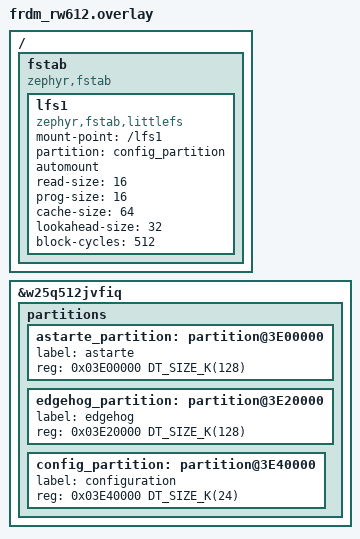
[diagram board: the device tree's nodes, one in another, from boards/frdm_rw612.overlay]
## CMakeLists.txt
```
# (C) Copyright 2025, SECO Mind Srl
#
# SPDX-License-Identifier: Apache-2.0

function(concat_if_exists FILE_PATH STRING_NAME)
    # Check if the file exists
    file(GLOB FILE_TO_ADD ${FILE_PATH})

    # If the file exists, add it to the list
    if(EXISTS ${FILE_TO_ADD})
        set(${STRING_NAME} "${${STRING_NAME}};${FILE_PATH}" PARENT_SCOPE)
    endif()
endfunction()

cmake_minimum_required(VERSION 3.20.0)

# add the sample specific private configuration
concat_if_exists(${CMAKE_SOURCE_DIR}/private.conf EXTRA_CONF_FILE)

find_package(Zephyr REQUIRED HINTS $ENV{ZEPHYR_BASE})
project(cpu_metrics_app)

test_sysbuild()

# create source files list
FILE(GLOB app_common_sources ${CMAKE_CURRENT_LIST_DIR}/src/*.c)
if(NOT CONFIG_WIFI)
    LIST(REMOVE_ITEM app_common_sources ${CMAKE_CURRENT_LIST_DIR}/src/wifi.c)
endif()
target_sources(app PRIVATE ${app_common_sources})
target_include_directories(app PRIVATE ${CMAKE_CURRENT_LIST_DIR}/include)

# add generated sources and includes for the interfaces
FILE(GLOB app_interfaces_sources ${CMAKE_CURRENT_LIST_DIR}/interfaces/*.c)
target_sources(app PRIVATE ${app_interfaces_sources})
target_include_directories(app PRIVATE ${CMAKE_CURRENT_LIST_DIR}/interfaces)
```

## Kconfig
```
menu "Zephyr"
source "Kconfig.zephyr"
endmenu

menu "CPU metrics sample application"

config GET_CONFIG_FROM_FLASH
    bool "Collect the configuration from flash"
    help
        Collect the configuration from a file in the dedicated flash partition.

config WIFI_SSID
    string "WiFi SSID"
	depends on WIFI
    depends on !GET_CONFIG_FROM_FLASH
    default ""
	help
	  WiFi access point SSID.

config WIFI_PASSWORD
    string "WiFi password"
	depends on WIFI
    depends on !GET_CONFIG_FROM_FLASH
    default ""
    help
        WiFi access point password.

config ENABLE_TRANSMISSION
    bool "Enable sensor readings transmission"
    default n
    help
        Enable transmission of sensor readings to Astarte.

config CPU_TEMP_SENSOR
    bool "CPU temperature sensor"
    default n
    help
        Temperature sensor embedded within the CPU die.

config AMBIENT_TEMP_SENSOR
    bool "Ambient temperature sensor"
    default n
    help
        Temperature sensor embedded within the ambient.

config ASTARTE_DEVICE_ID
	string "Astarte device ID"
    depends on !GET_CONFIG_FROM_FLASH
    default ""
	help
	  Device ID to be used to connect to Astarte.

config ASTARTE_CREDENTIAL_SECRET
    string "Astarte credential secret"
    depends on !GET_CONFIG_FROM_FLASH
    default ""
    help
        The credential secret to be used to connect to Astarte.

config SAMPLE_DURATION_SECONDS
    int "Sample maximum duration (s)"
    default 0
    help
        Use this setting to change for how long the sample will run.
        When set to 0 the sample will run indefinitely.

endmenu

module = APP
module-str = APP
source "subsys/logging/Kconfig.template.log_config"
```

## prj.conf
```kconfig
# (C) Copyright 2025, SECO Mind Srl
#
# SPDX-License-Identifier: Apache-2.0
#
# This is a Kconfig fragment which can be used to enable debug-related options
# in the application. See the README for more details.

# Enable logging with floating point support
CONFIG_LOG=y
CONFIG_CBPRINTF_FP_SUPPORT=y

# Increased stack size
CONFIG_MAIN_STACK_SIZE=8192

# Enable base64 encoding and decoding
CONFIG_BASE64=y

# Enable system hashmaps
CONFIG_SYS_HASH_MAP=y
CONFIG_SYS_HASH_FUNC32=y

# Enable JSON library
CONFIG_JSON_LIBRARY=y

# Enable entropy generator
CONFIG_ENTROPY_GENERATOR=y

# DNS resolver
CONFIG_DNS_RESOLVER=y
CONFIG_DNS_SERVER_IP_ADDRESSES=y
CONFIG_DNS_SERVER1="8.8.8.8" # Google DNS

# MbedTLS
CONFIG_MBEDTLS=y
CONFIG_MBEDTLS_BUILTIN=y
CONFIG_MBEDTLS_ENABLE_HEAP=y
# 55kB is the max absolute value, could be set much lower
CONFIG_MBEDTLS_HEAP_SIZE=95000
# 16384 is the max absolute value, could be set much lower
CONFIG_MBEDTLS_SSL_MAX_CONTENT_LEN=16384
CONFIG_MBEDTLS_PEM_CERTIFICATE_FORMAT=y
CONFIG_MBEDTLS_PK_WRITE_C=y # Required for PEM writing
CONFIG_MBEDTLS_ENTROPY_C=y
CONFIG_MBEDTLS_ENTROPY_POLL_ZEPHYR=y
CONFIG_MBEDTLS_TLS_VERSION_1_2=y
CONFIG_MBEDTLS_CIPHER=y
CONFIG_MBEDTLS_CIPHER_ALL_ENABLED=y
CONFIG_MBEDTLS_SERVER_NAME_INDICATION=y
CONFIG_MBEDTLS_KEY_EXCHANGE_ALL_ENABLED=y
CONFIG_MBEDTLS_HASH_ALL_ENABLED=y
CONFIG_MBEDTLS_CTR_DRBG_ENABLED=y
CONFIG_MBEDTLS_HMAC_DRBG_ENABLED=y
CONFIG_MBEDTLS_CHACHAPOLY_AEAD_ENABLED=y
CONFIG_MBEDTLS_ECDH_C=y
CONFIG_MBEDTLS_ECDSA_C=y
CONFIG_MBEDTLS_ECJPAKE_C=y
CONFIG_MBEDTLS_ECP_C=y
CONFIG_MBEDTLS_ECP_ALL_ENABLED=y
CONFIG_MBEDTLS_GENPRIME_ENABLED=y
CONFIG_MBEDTLS_PKCS5_C=y
CONFIG_MBEDTLS_X509_CRL_PARSE_C=y
CONFIG_MBEDTLS_X509_CSR_PARSE_C=y
CONFIG_MBEDTLS_X509_CSR_WRITE_C=y

# Enable networking
CONFIG_NETWORKING=y

# Sockets
CONFIG_NET_SOCKETS=y
CONFIG_NET_SOCKETS_POLL_MAX=4
CONFIG_NET_SOCKETS_SOCKOPT_TLS=y

# Use DHCP for IPv4 and IPv6
CONFIG_NET_DHCPV4=y
CONFIG_NET_DHCPV6=y

# Generic networking options
CONFIG_NET_TX_STACK_SIZE=4096
CONFIG_NET_RX_STACK_SIZE=4096
CONFIG_NET_PKT_RX_COUNT=20
CONFIG_NET_PKT_TX_COUNT=20
CONFIG_NET_BUF_RX_COUNT=40
CONFIG_NET_BUF_TX_COUNT=40
CONFIG_NET_MAX_CONTEXTS=20
CONFIG_NET_MGMT=y
CONFIG_NET_MGMT_EVENT=y
CONFIG_NET_IPV4=y
CONFIG_NET_IPV6=y
CONFIG_NET_TCP=y

# Enable HTTP client
CONFIG_HTTP_CLIENT=y

# MQTT options
CONFIG_MQTT_LIB=y
CONFIG_MQTT_LIB_TLS=y
CONFIG_MQTT_KEEPALIVE=60

# Enable flash
CONFIG_FLASH=y
CONFIG_FLASH_MAP=y
CONFIG_FLASH_PAGE_LAYOUT=y

# Enable NVS
CONFIG_NVS=y
CONFIG_NVS_LOG_LEVEL_WRN=y

# Astarte device SDK
CONFIG_ASTARTE_DEVICE_SDK=y
CONFIG_ASTARTE_DEVICE_SDK_HOSTNAME="."
CONFIG_ASTARTE_DEVICE_SDK_REALM_NAME="."
# The two certificate tags are the same as the root CA is the same for Astarte API and MQTT broker.
CONFIG_ASTARTE_DEVICE_SDK_HTTPS_CA_CERT_TAG=1
CONFIG_ASTARTE_DEVICE_SDK_MQTTS_CA_CERT_TAG=1
CONFIG_ASTARTE_DEVICE_SDK_CLIENT_CERT_TAG=2
CONFIG_ASTARTE_DEVICE_SDK_PAIRING_JWT=""
CONFIG_ASTARTE_DEVICE_SDK_PERMANENT_STORAGE=y

# Configure the name of the binary
# This will also be used to identify the edgehog image
CONFIG_KERNEL_BIN_NAME="frdm-rw612"

# Edgehog depends on
CONFIG_IMG_MANAGER=y
CONFIG_STREAM_FLASH=y
CONFIG_REBOOT=y

# Edgehog device
CONFIG_EDGEHOG_DEVICE=y
CONFIG_EDGEHOG_DEVICE_CA_CERT_OTA_TAG=3
CONFIG_EDGEHOG_DEVICE_ZBUS_OTA_EVENT=y

# System info interface data
CONFIG_EDGEHOG_DEVICE_PART_NUMBER="FRDM-RW612-X"
CONFIG_EDGEHOG_DEVICE_SERIAL_NUMBER=""

# Sample configuration
CONFIG_ASTARTE_DEVICE_ID="......................"
CONFIG_ASTARTE_CREDENTIAL_SECRET="."

CONFIG_DNS_RESOLVER_AI_MAX_ENTRIES=4
CONFIG_NET_SOCKETS_TLS_MAX_CONTEXTS=4

CONFIG_THREAD_MONITOR=y
CONFIG_INIT_STACKS=y
CONFIG_THREAD_STACK_INFO=y

CONFIG_ZVFS_OPEN_MAX=16

CONFIG_POSIX_TIMERS=y
CONFIG_SNTP=y
CONFIG_NET_CONFIG_CLOCK_SNTP_INIT=y
CONFIG_NET_CONFIG_SNTP_INIT_SERVER="0.pool.ntp.org"
CONFIG_NET_CONFIG_SNTP_INIT_TIMEOUT=3000

# Enable the settings
CONFIG_SETTINGS=y

# Activate Zbus
CONFIG_ZBUS=y

# Configuration for the CPU temperature sensor
CONFIG_SENSOR=y

# Configuration for the collection of CPU statistics
CONFIG_THREAD_RUNTIME_STATS=y
CONFIG_SCHED_THREAD_USAGE=y
CONFIG_SCHED_THREAD_USAGE_ALL=y
CONFIG_SCHED_THREAD_USAGE_ANALYSIS=y
CONFIG_SCHED_THREAD_USAGE_AUTO_ENABLE=y

# Enable littlefs
CONFIG_FILE_SYSTEM=y
CONFIG_FILE_SYSTEM_LITTLEFS=y

# Enabling shell
CONFIG_SHELL=y
CONFIG_SHELL_AUTOSTART=y
```

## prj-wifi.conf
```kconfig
# (C) Copyright 2025, SECO Mind Srl
#
# SPDX-License-Identifier: Apache-2.0
#
# This is a Kconfig fragment which can be used to enable debug-related options
# in the application. See the README for more details.

CONFIG_WIFI=y
CONFIG_ETH_DRIVER=n

CONFIG_NET_IPV6=n
CONFIG_NET_DHCPV6=n

# Increased stack size for network management
CONFIG_NET_MGMT_EVENT_STACK_SIZE=2048

# Large shell stack size used when configuring WiFi through shell
CONFIG_SHELL_STACK_SIZE=16384
CONFIG_SHELL_GETOPT=y
CONFIG_GETOPT_LONG=y
```

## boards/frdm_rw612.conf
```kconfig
# (C) Copyright 2025, SECO Mind Srl
#
# SPDX-License-Identifier: Apache-2.0

# Enable the WiFi
CONFIG_WIFI_NXP=y

# Use a large log buffer size
CONFIG_LOG_BUFFER_SIZE=32768

# Set the ambient temperature sensor in the demo
CONFIG_AMBIENT_TEMP_SENSOR=y

# This board by default will expect the configuration to be present in flash
CONFIG_GET_CONFIG_FROM_FLASH=y
```

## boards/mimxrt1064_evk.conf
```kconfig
# (C) Copyright 2025, SECO Mind Srl
#
# SPDX-License-Identifier: Apache-2.0

# Ethernet settings
CONFIG_NET_L2_ETHERNET=y
CONFIG_NET_L2_ETHERNET_MGMT=y

CONFIG_EDGEHOG_DEVICE_USE_EDGEHOG_PARTITION=y

CONFIG_LOG_MODE_DEFERRED=y
CONFIG_LOG_BUFFER_SIZE=32768

CONFIG_CPU_TEMP_SENSOR=y
```

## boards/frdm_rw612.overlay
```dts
/*
 * (C) Copyright 2025, SECO Mind Srl
 *
 * SPDX-License-Identifier: Apache-2.0
 */

/ {
    fstab {
        compatible = "zephyr,fstab";
        lfs1: lfs1 {
            compatible = "zephyr,fstab,littlefs";
            mount-point = "/lfs1";
            partition = <&config_partition>;
            automount;
            read-size = <16>;
            prog-size = <16>;
            cache-size = <64>;
            lookahead-size = <32>;
            block-cycles = <512>;
        };
    };
};

&w25q512jvfiq {
	partitions {
		astarte_partition: partition@3E00000 {
			label = "astarte";
			reg = <0x03E00000 DT_SIZE_K(128)>;
		};
		edgehog_partition: partition@3E20000 {
			label = "edgehog";
			reg = <0x03E20000 DT_SIZE_K(128)>;
		};
		config_partition: partition@3E40000 {
			label = "configuration";
			reg = <0x03E40000 DT_SIZE_K(24)>;
		};
	};
};
```

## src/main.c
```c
/*
 * (C) Copyright 2025, SECO Mind Srl
 *
 * SPDX-License-Identifier: Apache-2.0
 */

#include <zephyr/device.h>
#include <zephyr/drivers/sensor.h>
#include <zephyr/kernel.h>
#include <zephyr/logging/log.h>
#include <zephyr/net/net_mgmt.h>
#include <zephyr/net/sntp.h>
#include <zephyr/posix/time.h>
LOG_MODULE_REGISTER(cpu_metrics_app, CONFIG_APP_LOG_LEVEL);

#if (!defined(CONFIG_ASTARTE_DEVICE_SDK_DEVELOP_USE_NON_TLS_HTTP)                                  \
    || !defined(CONFIG_ASTARTE_DEVICE_SDK_DEVELOP_USE_NON_TLS_MQTT))
#include <zephyr/net/tls_credentials.h>

#include "ca_certificates.h"
#endif

#include <astarte_device_sdk/device.h>

#ifdef CONFIG_EDGEHOG_DEVICE_ZBUS_OTA_EVENT
#include <edgehog_device/ota_event.h>
#endif
#include <edgehog_device/device.h>
#include <edgehog_device/telemetry.h>

#if defined(CONFIG_WIFI)
#include "wifi.h"
#else
#include "eth.h"
#endif
#include "generated_interfaces.h"

#include "sample_config.h"

/************************************************
 * Constants and defines
 ***********************************************/

#define MAIN_THREAD_PERIOD_MS 500
#define EDGEHOG_DEVICE_PERIOD_MS 100
#ifdef CONFIG_EDGEHOG_DEVICE_ZBUS_OTA_EVENT
#define ZBUS_PERIOD_MS 500
#endif

#define HTTP_TIMEOUT_MS (3 * MSEC_PER_SEC)
#define MQTT_FIRST_POLL_TIMEOUT_MS (3 * MSEC_PER_SEC)
#define MQTT_POLL_TIMEOUT_MS 200

#define TELEMETRY_PERIOD_S 5

#define EDGEHOG_DEVICE_THREAD_STACK_SIZE 16384
#define EDGEHOG_DEVICE_THREAD_PRIORITY 0
K_THREAD_STACK_DEFINE(edgehog_device_thread_stack_area, EDGEHOG_DEVICE_THREAD_STACK_SIZE);
static struct k_thread edgehog_device_thread_data;

#ifdef CONFIG_EDGEHOG_DEVICE_ZBUS_OTA_EVENT
#define ZBUS_THREAD_STACK_SIZE 16384
#define ZBUS_THREAD_PRIORITY 0
K_THREAD_STACK_DEFINE(zbus_thread_stack_area, ZBUS_THREAD_STACK_SIZE);
static struct k_thread zbus_thread_data;
#define EDGEHOG_OTA_SUBSCRIBER_NOTIFICATION_QUEUE_SIZE 5
#define EDGEHOG_OTA_OBSERVER_NOTIFY_PRIORITY 5
ZBUS_SUBSCRIBER_DEFINE(edgehog_ota_subscriber, EDGEHOG_OTA_SUBSCRIBER_NOTIFICATION_QUEUE_SIZE);
ZBUS_CHAN_ADD_OBS(edgehog_ota_chan, edgehog_ota_subscriber, EDGEHOG_OTA_OBSERVER_NOTIFY_PRIORITY);
#endif

#define STATS_THREAD_STACK_SIZE 16384
#define STATS_THREAD_PRIORITY 0
K_THREAD_STACK_DEFINE(stats_thread_stack_area, STATS_THREAD_STACK_SIZE);
static struct k_thread stats_thread_data;

#ifdef CONFIG_CPU_TEMP_SENSOR
static const struct device *const die_temp_sensor = DEVICE_DT_GET(DT_ALIAS(die_temp0));
#endif
#ifdef CONFIG_AMBIENT_TEMP_SENSOR
static const struct device *const ambient_temp_sensor = DEVICE_DT_GET(DT_ALIAS(ambient_temp0));
#endif

enum device_tread_flags
{
    DEVICE_THREADS_FLAGS_TERMINATION = 1U,
    DEVICE_THREADS_FLAGS_ASTARTE_CONNECTED,
};
static atomic_t device_threads_flags;

static edgehog_device_handle_t edgehog_device;

/************************************************
 * Static functions declaration
 ***********************************************/

/**
 * @brief Initialize System Time
 */
static void system_time_init(void);
/**
 * @brief Entry point for the Astarte device thread.
 *
 * @param arg1 Unused argument.
 * @param arg2 Unused argument.
 * @param arg3 Unused argument.
 */
static void edgehog_device_thread_entry_point(void *device_id, void *cred_secr, void *arg3);
#ifdef CONFIG_EDGEHOG_DEVICE_ZBUS_OTA_EVENT
/**
 * @brief Entry point for the Zbus reception thread.
 *
 * @param arg1 Unused argument.
 * @param arg2 Unused argument.
 * @param arg3 Unused argument.
 */
static void zbus_thread_entry_point(void *arg1, void *arg2, void *arg3);
#endif
#ifdef CONFIG_EDGEHOG_DEVICE_ZBUS_OTA_EVENT
/**
 * @brief Listen on the Edgehog zbus channel for events.
 *
 * @param timeout The timeout used for listening. In case of a received notification this timeout
 * is also used for reading the message.
 */
static void edgehog_listen_zbus_channel(k_timeout_t timeout);
#endif
/**
 * @brief Callback handler for Astarte connection events.
 *
 * @param event Astarte device connection event.
 */
static void astarte_connection_callback(astarte_device_connection_event_t event);
/**
 * @brief Callback handler for Astarte disconnection events.
 *
 * @param event Astarte device disconnection event.
 */
static void astarte_disconnection_callback(astarte_device_disconnection_event_t event);
/**
 * @brief Entry point for the stats thread.
 *
 * @param arg1 Unused argument.
 * @param arg2 Unused argument.
 * @param arg3 Unused argument.
 */
static void stats_thread_entry_point(void *arg1, void *arg2, void *arg3);

/************************************************
 * Global functions definition
 ***********************************************/

// NOLINTNEXTLINE(hicpp-function-size)
int main(void)
{
    LOG_INF("Edgehog device sample");
    LOG_INF("Board: %s", CONFIG_BOARD);

    struct sample_config cfg_from_file = { 0 };
    sample_config_get(&cfg_from_file);
    LOG_INF("Configured device ID: %s", cfg_from_file.device_id);
    LOG_INF("Configured credential secret: %s", cfg_from_file.credential_secret);
#if defined(CONFIG_WIFI)
    LOG_INF("Configured WiFi SSID: %s", cfg_from_file.wifi_ssid);
    LOG_INF("Configured WiFi password: %s", cfg_from_file.wifi_pwd);
#endif

#ifdef CONFIG_CPU_TEMP_SENSOR
    if (!device_is_ready(die_temp_sensor)) {
        LOG_ERR("sensor: device %s not ready.", die_temp_sensor->name);
        return -ENODEV;
    }
#endif
#ifdef CONFIG_AMBIENT_TEMP_SENSOR
    if (!device_is_ready(ambient_temp_sensor)) {
        LOG_ERR("sensor: device %s not ready.", ambient_temp_sensor->name);
        return -ENODEV;
    }
#endif

#if defined(CONFIG_WIFI)
    LOG_INF("Initializing WiFi driver."); // NOLINT
    app_wifi_init();
    k_sleep(K_SECONDS(5));
    enum wifi_security_type sec = WIFI_SECURITY_TYPE_PSK;
    if (app_wifi_connect(cfg_from_file.wifi_ssid, sec, cfg_from_file.wifi_pwd) != 0) {
        LOG_ERR("Connectivity intialization failed!"); // NOLINT
        return -1;
    }
#else
    LOG_INF("Initializing Ethernet driver."); // NOLINT
    if (eth_connect() != 0) {
        LOG_ERR("Connectivity intialization failed!"); // NOLINT
        return -1;
    }
#endif

    // Add TLS certificate for Astarte if required
#if (!defined(CONFIG_ASTARTE_DEVICE_SDK_DEVELOP_USE_NON_TLS_HTTP)                                  \
    || !defined(CONFIG_ASTARTE_DEVICE_SDK_DEVELOP_USE_NON_TLS_MQTT))
    tls_credential_add(CONFIG_ASTARTE_DEVICE_SDK_HTTPS_CA_CERT_TAG, TLS_CREDENTIAL_CA_CERTIFICATE,
        ca_certificate_root, sizeof(ca_certificate_root));
#endif
    // Add TLS certificate for Edgehog if required
#if !defined(CONFIG_EDGEHOG_DEVICE_DEVELOP_DISABLE_OR_IGNORE_TLS)
    tls_credential_add(CONFIG_EDGEHOG_DEVICE_CA_CERT_OTA_TAG, TLS_CREDENTIAL_CA_CERTIFICATE,
        ota_ca_certificate_root, sizeof(ota_ca_certificate_root));
#endif

    // Initalize the system time
    system_time_init();

    // Spawn a new thread for the Edgehog device
    k_thread_create(&edgehog_device_thread_data, edgehog_device_thread_stack_area,
        K_THREAD_STACK_SIZEOF(edgehog_device_thread_stack_area), edgehog_device_thread_entry_point,
        cfg_from_file.device_id, cfg_from_file.credential_secret, NULL,
        EDGEHOG_DEVICE_THREAD_PRIORITY, 0, K_NO_WAIT);

    // Spawn a new thread for the stats
    k_thread_create(&stats_thread_data, stats_thread_stack_area,
        K_THREAD_STACK_SIZEOF(stats_thread_stack_area), stats_thread_entry_point, NULL, NULL, NULL,
        STATS_THREAD_PRIORITY, 0, K_NO_WAIT);

    // Wait for a predefined operational time.
    k_timeout_t finish_timeout = (CONFIG_SAMPLE_DURATION_SECONDS == 0)
        ? K_FOREVER
        : K_SECONDS(CONFIG_SAMPLE_DURATION_SECONDS);
    k_timepoint_t finish_timepoint = sys_timepoint_calc(finish_timeout);
    while (!K_TIMEOUT_EQ(sys_timepoint_timeout(finish_timepoint), K_NO_WAIT)) {
        k_timepoint_t timepoint = sys_timepoint_calc(K_MSEC(MAIN_THREAD_PERIOD_MS));
#if !defined(CONFIG_WIFI)
        eth_poll();
#endif
        k_sleep(sys_timepoint_timeout(timepoint));
    }

    // Signal to the Device threads that they should terminate.
    atomic_set_bit(&device_threads_flags, DEVICE_THREADS_FLAGS_TERMINATION);

    // Wait for the Edgehog thread to terminate.
    if (k_thread_join(&edgehog_device_thread_data, K_FOREVER) != 0) {
        LOG_ERR("Failed in waiting for the Edgehog thread to terminate.");
    }

    LOG_INF("Edgehog device sample finished.");
    k_sleep(K_MSEC(MSEC_PER_SEC));

    return 0;
}

/************************************************
 * Static functions definitions
 ***********************************************/

static void system_time_init()
{
#ifdef CONFIG_SNTP
    int ret = 0;
    struct sntp_time now;
    struct timespec tspec;

    ret = sntp_simple(
        CONFIG_NET_CONFIG_SNTP_INIT_SERVER, CONFIG_NET_CONFIG_SNTP_INIT_TIMEOUT, &now);
    if (ret == 0) {
        tspec.tv_sec = (time_t) now.seconds;
        // NOLINTBEGIN(bugprone-narrowing-conversions, hicpp-signed-bitwise,
        // readability-magic-numbers)
        tspec.tv_nsec = ((uint64_t) now.fraction * (1000lu * 1000lu * 1000lu)) >> 32;
        // NOLINTEND(bugprone-narrowing-conversions, hicpp-signed-bitwise,
        // readability-magic-numbers)
        clock_settime(CLOCK_REALTIME, &tspec);
    }
#endif
}

static void edgehog_device_thread_entry_point(void *device_id, void *cred_secr, void *arg3)
{
    ARG_UNUSED(arg3);

    // Configuring the Astarte device used by the Edgehog device to communicate with the cloud
    // Edgehog instance. This device can also be leveraged by the user to send and receive data
    // through Astarte, check out the sample README for more information.

    const astarte_interface_t *interfaces[] = {
        &com_example_poc_CpuMetrics,
#ifdef CONFIG_CPU_TEMP_SENSOR
        &com_example_poc_CpuTemp,
#endif
#ifdef CONFIG_AMBIENT_TEMP_SENSOR
        &com_example_poc_AmbientTemp,
#endif
    };

    astarte_device_config_t astarte_device_config = { 0 };
    astarte_device_config.http_timeout_ms = HTTP_TIMEOUT_MS;
    astarte_device_config.mqtt_connection_timeout_ms = MQTT_FIRST_POLL_TIMEOUT_MS;
    astarte_device_config.mqtt_poll_timeout_ms = MQTT_POLL_TIMEOUT_MS;
    astarte_device_config.connection_cbk = astarte_connection_callback;
    astarte_device_config.disconnection_cbk = astarte_disconnection_callback;
    astarte_device_config.interfaces = interfaces;
    astarte_device_config.interfaces_size = ARRAY_SIZE(interfaces);
    memcpy(astarte_device_config.cred_secr, cred_secr, ASTARTE_PAIRING_CRED_SECR_LEN + 1);
    memcpy(astarte_device_config.device_id, device_id, ASTARTE_DEVICE_ID_LEN + 1);

    edgehog_result_t eres = EDGEHOG_RESULT_OK;

    edgehog_telemetry_config_t telemetry_config = {
        .type = EDGEHOG_TELEMETRY_SYSTEM_STATUS,
        .period_seconds = TELEMETRY_PERIOD_S,
    };
    edgehog_device_config_t edgehog_conf = {
        .astarte_device_config = astarte_device_config,
        .telemetry_config = &telemetry_config,
        .telemetry_config_len = 1,
    };
    eres = edgehog_device_new(&edgehog_conf, &edgehog_device);
    if (eres != EDGEHOG_RESULT_OK) {
        LOG_ERR("Unable to create edgehog device handle");
        goto exit;
    }

    eres = edgehog_device_start(edgehog_device);
    if (eres != EDGEHOG_RESULT_OK) {
        LOG_ERR("Unable to start edgehog device");
        goto exit;
    }

#ifdef CONFIG_EDGEHOG_DEVICE_ZBUS_OTA_EVENT
    // Spawn a new thread for listening on Zbus device
    k_thread_create(&zbus_thread_data, zbus_thread_stack_area,
        K_THREAD_STACK_SIZEOF(zbus_thread_stack_area), zbus_thread_entry_point, NULL, NULL, NULL,
        ZBUS_THREAD_PRIORITY, 0, K_NO_WAIT);
#endif

    while (!atomic_test_bit(&device_threads_flags, DEVICE_THREADS_FLAGS_TERMINATION)) {
        k_timepoint_t timepoint = sys_timepoint_calc(K_MSEC(EDGEHOG_DEVICE_PERIOD_MS));

        eres = edgehog_device_poll(edgehog_device);
        if (eres != EDGEHOG_RESULT_OK) {
            LOG_ERR("Edgehog device poll failure.");
            goto exit;
        }

        k_sleep(sys_timepoint_timeout(timepoint));
    }

    LOG_INF("End of sample, stopping Edgehog.");
    eres = edgehog_device_stop(edgehog_device, K_FOREVER);
    if (eres != EDGEHOG_RESULT_OK) {
        LOG_ERR("Unable to stop the edgehog device");
        goto exit;
    }

    LOG_INF("Edgehog device will now be destroyed.");
    edgehog_device_destroy(edgehog_device);

exit:
    // Ensure to set the thread termination flag
    atomic_set_bit(&device_threads_flags, DEVICE_THREADS_FLAGS_TERMINATION);

#ifdef CONFIG_EDGEHOG_DEVICE_ZBUS_OTA_EVENT
    // Wait for the Zbus thread to terminate.
    if (k_thread_join(&zbus_thread_data, K_SECONDS(10)) != 0) {
        LOG_ERR("Failed in waiting for the Zbus thread to terminate.");
    }
#endif
}

#ifdef CONFIG_EDGEHOG_DEVICE_ZBUS_OTA_EVENT
static void zbus_thread_entry_point(void *arg1, void *arg2, void *arg3)
{
    ARG_UNUSED(arg1);
    ARG_UNUSED(arg2);
    ARG_UNUSED(arg3);

    while (!atomic_test_bit(&device_threads_flags, DEVICE_THREADS_FLAGS_TERMINATION)) {
        edgehog_listen_zbus_channel(K_MSEC(ZBUS_PERIOD_MS));
    }
}
#endif

#ifdef CONFIG_EDGEHOG_DEVICE_ZBUS_OTA_EVENT
static void edgehog_listen_zbus_channel(k_timeout_t timeout)
{
    const struct zbus_channel *chan = NULL;
    edgehog_ota_chan_event_t ota = { 0 };
    if ((zbus_sub_wait(&edgehog_ota_subscriber, &chan, timeout) == 0) && (&edgehog_ota_chan == chan)
        && (zbus_chan_read(chan, &ota, timeout) == 0)) {
        switch (ota.event) {
            case EDGEHOG_OTA_INIT_EVENT:
                LOG_WRN("To subscriber -> EDGEHOG_OTA_INIT_EVENT");
                break;
            case EDGEHOG_OTA_PENDING_REBOOT_EVENT:
                LOG_WRN("To subscriber -> EDGEHOG_OTA_PENDING_REBOOT_EVENT");
                edgehog_ota_chan_event_t ota_chan_event
                    = { .event = EDGEHOG_OTA_CONFIRM_REBOOT_EVENT };
                zbus_chan_pub(&edgehog_ota_chan, &ota_chan_event, K_SECONDS(1));
                break;
            case EDGEHOG_OTA_CONFIRM_REBOOT_EVENT:
                LOG_WRN("To subscriber -> EDGEHOG_OTA_CONFIRM_REBOOT_EVENT");
                break;
            case EDGEHOG_OTA_FAILED_EVENT:
                LOG_WRN("To subscriber -> EDGEHOG_OTA_FAILED_EVENT");
                break;
            case EDGEHOG_OTA_SUCCESS_EVENT:
                LOG_WRN("To subscriber -> EDGEHOG_OTA_SUCCESS_EVENT");
                break;
            default:
                LOG_WRN("To subscriber -> EDGEHOG_OTA_INVALID_EVENT");
        }
    }
}
#endif

static void astarte_connection_callback(astarte_device_connection_event_t event)
{
    ARG_UNUSED(event);
    LOG_INF("Astarte device connected.");
    atomic_set_bit(&device_threads_flags, DEVICE_THREADS_FLAGS_ASTARTE_CONNECTED);
}

static void astarte_disconnection_callback(astarte_device_disconnection_event_t event)
{
    ARG_UNUSED(event);
    LOG_INF("Astarte device disconnected");
    atomic_clear_bit(&device_threads_flags, DEVICE_THREADS_FLAGS_ASTARTE_CONNECTED);
}

static void stats_thread_entry_point(void *arg1, void *arg2, void *arg3)
{
    while (!atomic_test_bit(&device_threads_flags, DEVICE_THREADS_FLAGS_TERMINATION)) {
        k_timepoint_t timepoint = sys_timepoint_calc(K_SECONDS(5));

        int ret;
#ifdef CONFIG_ENABLE_TRANSMISSION
        astarte_result_t ares = ASTARTE_RESULT_OK;
#endif

        if (!atomic_test_bit(&device_threads_flags, DEVICE_THREADS_FLAGS_ASTARTE_CONNECTED)) {
            LOG_ERR("Skipping stats transmission, Astarte is not connected.");
            k_sleep(sys_timepoint_timeout(timepoint));
            continue;
        }

        int64_t timestamp_ms = 0;
        struct timespec tspec;
        ret = clock_gettime(CLOCK_REALTIME, &tspec);
        if (ret != 0) {
            LOG_ERR("Failed getting time.");
        }
        timestamp_ms = (int64_t) tspec.tv_sec * MSEC_PER_SEC + (tspec.tv_nsec / NSEC_PER_MSEC);

#ifdef CONFIG_ENABLE_TRANSMISSION
        astarte_device_handle_t astarte_device = edgehog_device_get_astarte_device(edgehog_device);
#endif

        static uint64_t prev_total_cycles = 0U; // Non idle cycles
        static uint64_t prev_execution_cycles = 0U; // Sum of idle + non idle cycles

        k_thread_runtime_stats_t stats;
        ret = k_thread_runtime_stats_cpu_get(0, &stats);
        if (ret) {
            LOG_ERR("Failed reading CPU stats (%d)", ret);
        } else {
            double cpu_usage = 100.0f * (stats.total_cycles - prev_total_cycles)
                / (stats.execution_cycles - prev_execution_cycles);
            prev_total_cycles = stats.total_cycles;
            prev_execution_cycles = stats.execution_cycles;

            LOG_INF("CPU usage: %.2lf %%", cpu_usage);

#ifdef CONFIG_ENABLE_TRANSMISSION
            ares = astarte_device_send_individual(astarte_device, com_example_poc_CpuMetrics.name,
                "/loadavg", astarte_data_from_double(cpu_usage), &timestamp_ms);
            if (ares != ASTARTE_RESULT_OK) {
                LOG_ERR("Astarte device transmission failure.");
            }
#else
            LOG_INF("Data transmission is disabled.");
#endif
        }

#ifdef CONFIG_CPU_TEMP_SENSOR
        ret = sensor_sample_fetch(die_temp_sensor);
        if (ret) {
            LOG_ERR("Failed to fetch temperature sample (%d)", ret);
            return;
        }

        struct sensor_value die_temp_val;
        ret = sensor_channel_get(die_temp_sensor, SENSOR_CHAN_DIE_TEMP, &die_temp_val);
        if (ret) {
            LOG_ERR("Failed to get temperature reading (%d)", ret);
            return;
        }

        double die_temp = sensor_value_to_double(&die_temp_val);
        LOG_INF("CPU Die temperature: %.1f °C", die_temp);

#ifdef CONFIG_ENABLE_TRANSMISSION
        ares = astarte_device_send_individual(astarte_device, com_example_poc_CpuTemp.name, "/temp",
            astarte_data_from_double(die_temp), &timestamp_ms);
        if (ares != ASTARTE_RESULT_OK) {
            LOG_ERR("Astarte device transmission failure.");
        }
#else
        LOG_INF("Data transmission is disabled.");
#endif
#endif
#ifdef CONFIG_AMBIENT_TEMP_SENSOR
        ret = sensor_sample_fetch_chan(ambient_temp_sensor, SENSOR_CHAN_AMBIENT_TEMP);
        if (ret) {
            LOG_ERR("Failed to fetch temperature sample (%d)", ret);
            return;
        }

        struct sensor_value ambient_temp_val;
        ret = sensor_channel_get(ambient_temp_sensor, SENSOR_CHAN_AMBIENT_TEMP, &ambient_temp_val);
        if (ret) {
            LOG_ERR("Failed to get temperature reading (%d)", ret);
            return;
        }

        double ambient_temp = sensor_value_to_double(&ambient_temp_val);
        LOG_INF("Ambient temperature: %.1f °C", ambient_temp);

#ifdef CONFIG_ENABLE_TRANSMISSION
        ares = astarte_device_send_individual(astarte_device, com_example_poc_AmbientTemp.name,
            "/temp", astarte_data_from_double(ambient_temp), &timestamp_ms);
        if (ares != ASTARTE_RESULT_OK) {
            LOG_ERR("Astarte device transmission failure.");
        }
#else
        LOG_INF("Data transmission is disabled.");
#endif
#endif

        k_sleep(sys_timepoint_timeout(timepoint));
    }
}
```

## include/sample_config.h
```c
/*
 * (C) Copyright 2025, SECO Mind Srl
 *
 * SPDX-License-Identifier: Apache-2.0
 */

#ifndef SAMPLE_CONFIG_H
#define SAMPLE_CONFIG_H

#include <stdbool.h>
#include <stddef.h>

#include <astarte_device_sdk/device.h>

#if defined(CONFIG_WIFI)
#define SAMPLE_CONFIG_WIFI_MAX_STRINGS 255
#endif

struct sample_config
{
    char device_id[ASTARTE_DEVICE_ID_LEN + 1];
#if !defined(CONFIG_DEVICE_REGISTRATION)
    char credential_secret[ASTARTE_PAIRING_CRED_SECR_LEN + 1];
#endif
#if defined(CONFIG_WIFI)
    char wifi_ssid[SAMPLE_CONFIG_WIFI_MAX_STRINGS];
    char wifi_pwd[SAMPLE_CONFIG_WIFI_MAX_STRINGS];
#endif
};

int sample_config_get(struct sample_config *cfg);
#if defined(CONFIG_WIFI)
int sample_config_get_wifi_ssid(char output[static SAMPLE_CONFIG_WIFI_MAX_STRINGS]);
int sample_config_update_wifi_creds(char ssid[static SAMPLE_CONFIG_WIFI_MAX_STRINGS],
    char pwd[static SAMPLE_CONFIG_WIFI_MAX_STRINGS]);
#endif

#endif /* SAMPLE_CONFIG_H */
```

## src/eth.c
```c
/*
 * (C) Copyright 2025, SECO Mind Srl
 *
 * SPDX-License-Identifier: Apache-2.0
 */

#include "eth.h"

#include <zephyr/kernel.h>
#include <zephyr/net/ethernet.h>
#include <zephyr/net/ethernet_mgmt.h>
#include <zephyr/version.h>

#include <zephyr/logging/log.h>
LOG_MODULE_REGISTER(eth, CONFIG_APP_LOG_LEVEL); // NOLINT

/************************************************
 *        Constants, statics and defines        *
 ***********************************************/

// NOLINTBEGIN(cppcoreguidelines-avoid-non-const-global-variables)
static struct net_mgmt_event_callback eth_cb;
static struct net_mgmt_event_callback status_cb;
static struct net_mgmt_event_callback ipv6_cb;
static struct net_mgmt_event_callback ipv4_cb;
static struct net_mgmt_event_callback l4_cb;

static K_SEM_DEFINE(ipv4_address_obtained, 0, 1);
// NOLINTEND(cppcoreguidelines-avoid-non-const-global-variables)

/************************************************
 *       Callbacks declaration/definition       *
 ***********************************************/

#if (KERNEL_VERSION_MAJOR >= 4) && (KERNEL_VERSION_MINOR >= 2)
static void eth_mgmt_event_handler(
    struct net_mgmt_event_callback *event_cb, uint64_t mgmt_event, struct net_if *iface)
#else
static void eth_mgmt_event_handler(
    struct net_mgmt_event_callback *event_cb, uint32_t mgmt_event, struct net_if *iface)
#endif
{
    (void) event_cb;
    (void) iface;

    // NOLINTBEGIN(hicpp-signed-bitwise)
    switch (mgmt_event) {
        case NET_EVENT_ETHERNET_CARRIER_ON:
            LOG_DBG("Ethernet event: NET_EVENT_ETHERNET_CARRIER_ON."); // NOLINT
            break;

        case NET_EVENT_ETHERNET_CARRIER_OFF:
            LOG_DBG("Ethernet event: NET_EVENT_ETHERNET_CARRIER_OFF."); // NOLINT
            break;

        case NET_EVENT_ETHERNET_VLAN_TAG_ENABLED:
            LOG_DBG("Ethernet event: NET_EVENT_ETHERNET_VLAN_TAG_ENABLED."); // NOLINT
            break;

        case NET_EVENT_ETHERNET_VLAN_TAG_DISABLED:
            LOG_DBG("Ethernet event: NET_EVENT_ETHERNET_VLAN_TAG_DISABLED."); // NOLINT
            break;

        default:
#if (KERNEL_VERSION_MAJOR >= 4) && (KERNEL_VERSION_MINOR >= 2)
            LOG_DBG("Status network event: %lld.", mgmt_event); // NOLINT
#else
            LOG_DBG("Status network event: %d.", mgmt_event); // NOLINT
#endif
            break;
    }
    // NOLINTEND(hicpp-signed-bitwise)
}

#if (KERNEL_VERSION_MAJOR >= 4) && (KERNEL_VERSION_MINOR >= 2)
static void status_mgmt_event_handler(
    struct net_mgmt_event_callback *event_cb, uint64_t mgmt_event, struct net_if *iface)
#else
static void status_mgmt_event_handler(
    struct net_mgmt_event_callback *event_cb, uint32_t mgmt_event, struct net_if *iface)
#endif
{
    (void) event_cb;
    (void) iface;

    // NOLINTBEGIN(hicpp-signed-bitwise)
    switch (mgmt_event) {
        case NET_EVENT_IF_DOWN:
            LOG_DBG("Network event: NET_EVENT_IF_DOWN."); // NOLINT
            break;

        case NET_EVENT_IF_UP:
            LOG_DBG("Network event: NET_EVENT_IF_UP."); // NOLINT
            break;

        case NET_EVENT_IF_ADMIN_DOWN:
            LOG_DBG("Network event: NET_EVENT_IF_ADMIN_DOWN."); // NOLINT
            break;

        case NET_EVENT_IF_ADMIN_UP:
            LOG_DBG("Network event: NET_EVENT_IF_ADMIN_UP."); // NOLINT
            break;

        default:
#if (KERNEL_VERSION_MAJOR >= 4) && (KERNEL_VERSION_MINOR >= 2)
            LOG_DBG("Status network event: %lld.", mgmt_event); // NOLINT
#else
            LOG_DBG("Status network event: %d.", mgmt_event); // NOLINT
#endif
            break;
    }
    // NOLINTEND(hicpp-signed-bitwise)
}

#if (KERNEL_VERSION_MAJOR >= 4) && (KERNEL_VERSION_MINOR >= 2)
static void ipv6_mgmt_event_handler(
    struct net_mgmt_event_callback *event_cb, uint64_t mgmt_event, struct net_if *iface)
#else
static void ipv6_mgmt_event_handler(
    struct net_mgmt_event_callback *event_cb, uint32_t mgmt_event, struct net_if *iface)
#endif
{
    (void) event_cb;
    (void) iface;

    // NOLINTBEGIN(hicpp-signed-bitwise)
    switch (mgmt_event) {

        case NET_EVENT_IPV6_ADDR_ADD:
            LOG_DBG("IPv6 network event: NET_EVENT_IPV6_ADDR_ADD."); // NOLINT
            break;

        case NET_EVENT_IPV6_ADDR_DEL:
            LOG_DBG("IPv6 network event: NET_EVENT_IPV6_ADDR_DEL."); // NOLINT
            break;

        case NET_EVENT_IPV6_MADDR_ADD:
            LOG_DBG("IPv6 network event: NET_EVENT_IPV6_MADDR_ADD."); // NOLINT
            break;

        case NET_EVENT_IPV6_MADDR_DEL:
            LOG_DBG("IPv6 network event: NET_EVENT_IPV6_MADDR_DEL."); // NOLINT
            break;

        case NET_EVENT_IPV6_PREFIX_ADD:
            LOG_DBG("IPv6 network event: NET_EVENT_IPV6_PREFIX_ADD."); // NOLINT
            break;

        case NET_EVENT_IPV6_PREFIX_DEL:
            LOG_DBG("IPv6 network event: NET_EVENT_IPV6_PREFIX_DEL."); // NOLINT
            break;

        case NET_EVENT_IPV6_MCAST_JOIN:
            LOG_DBG("IPv6 network event: NET_EVENT_IPV6_MCAST_JOIN."); // NOLINT
            break;

        case NET_EVENT_IPV6_MCAST_LEAVE:
            LOG_DBG("IPv6 network event: NET_EVENT_IPV6_MCAST_LEAVE."); // NOLINT
            break;

        case NET_EVENT_IPV6_ROUTER_ADD:
            LOG_DBG("IPv6 network event: NET_EVENT_IPV6_ROUTER_ADD."); // NOLINT
            break;

        case NET_EVENT_IPV6_ROUTER_DEL:
            LOG_DBG("IPv6 network event: NET_EVENT_IPV6_ROUTER_DEL."); // NOLINT
            break;

        case NET_EVENT_IPV6_ROUTE_ADD:
            LOG_DBG("IPv6 network event: NET_EVENT_IPV6_ROUTE_ADD."); // NOLINT
            break;

        case NET_EVENT_IPV6_ROUTE_DEL:
            LOG_DBG("IPv6 network event: NET_EVENT_IPV6_ROUTE_DEL."); // NOLINT
            break;

        case NET_EVENT_IPV6_DAD_SUCCEED:
            LOG_DBG("IPv6 network event: NET_EVENT_IPV6_DAD_SUCCEED."); // NOLINT
            break;

        case NET_EVENT_IPV6_DAD_FAILED:
            LOG_DBG("IPv6 network event: NET_EVENT_IPV6_DAD_FAILED."); // NOLINT
            break;

        case NET_EVENT_IPV6_NBR_ADD:
            LOG_DBG("IPv6 network event: NET_EVENT_IPV6_NBR_ADD."); // NOLINT
            break;

        case NET_EVENT_IPV6_NBR_DEL:
            LOG_DBG("IPv6 network event: NET_EVENT_IPV6_NBR_DEL."); // NOLINT
            break;

        case NET_EVENT_IPV6_DHCP_START:
            LOG_DBG("IPv6 network event: NET_EVENT_IPV6_DHCP_START."); // NOLINT
            break;

        case NET_EVENT_IPV6_DHCP_BOUND:
            LOG_DBG("IPv6 network event: NET_EVENT_IPV6_DHCP_BOUND."); // NOLINT
            break;

        case NET_EVENT_IPV6_DHCP_STOP:
            LOG_DBG("IPv6 network event: NET_EVENT_IPV6_DHCP_STOP."); // NOLINT
            break;

        default:
#if (KERNEL_VERSION_MAJOR >= 4) && (KERNEL_VERSION_MINOR >= 2)
            LOG_DBG("IPv6 network event: %lld.", mgmt_event); // NOLINT
#else
            LOG_DBG("IPv6 network event: %d.", mgmt_event); // NOLINT
#endif
            break;
    }
    // NOLINTEND(hicpp-signed-bitwise)
}

#if (KERNEL_VERSION_MAJOR >= 4) && (KERNEL_VERSION_MINOR >= 2)
static void ipv4_mgmt_event_handler(
    struct net_mgmt_event_callback *event_cb, uint64_t mgmt_event, struct net_if *iface)
#else
static void ipv4_mgmt_event_handler(
    struct net_mgmt_event_callback *event_cb, uint32_t mgmt_event, struct net_if *iface)
#endif
{
    (void) event_cb;
    (void) iface;

    // NOLINTBEGIN(hicpp-signed-bitwise)
    switch (mgmt_event) {

        case NET_EVENT_IPV4_ADDR_ADD:
            LOG_DBG("Network event: NET_EVENT_IPV4_ADDR_ADD."); // NOLINT
            k_sem_give(&ipv4_address_obtained);
            break;

        case NET_EVENT_IPV4_ADDR_DEL:
            LOG_DBG("Network event: NET_EVENT_IPV4_ADDR_DEL."); // NOLINT
            k_sem_take(&ipv4_address_obtained, K_NO_WAIT);
            break;

        case NET_EVENT_IPV4_MADDR_ADD:
            LOG_DBG("Network event: NET_EVENT_IPV4_MADDR_ADD."); // NOLINT
            break;

        case NET_EVENT_IPV4_MADDR_DEL:
            LOG_DBG("Network event: NET_EVENT_IPV4_MADDR_DEL."); // NOLINT
            break;

        case NET_EVENT_IPV4_ROUTER_ADD:
            LOG_DBG("Network event: NET_EVENT_IPV4_ROUTER_ADD."); // NOLINT
            break;

        case NET_EVENT_IPV4_ROUTER_DEL:
            LOG_DBG("Network event: NET_EVENT_IPV4_ROUTER_DEL."); // NOLINT
            break;

        case NET_EVENT_IPV4_DHCP_START:
            LOG_DBG("Network event: NET_EVENT_IPV4_DHCP_START."); // NOLINT
            break;

        case NET_EVENT_IPV4_DHCP_BOUND:
            LOG_DBG("Network event: NET_EVENT_IPV4_DHCP_BOUND."); // NOLINT
            break;

        case NET_EVENT_IPV4_DHCP_STOP:
            LOG_DBG("Network event: NET_EVENT_IPV4_DHCP_STOP."); // NOLINT
            break;

        case NET_EVENT_IPV4_MCAST_JOIN:
            LOG_DBG("Network event: NET_EVENT_IPV4_MCAST_JOIN."); // NOLINT
            break;

        case NET_EVENT_IPV4_MCAST_LEAVE:
            LOG_DBG("Network event: NET_EVENT_IPV4_MCAST_LEAVE."); // NOLINT
            break;

        default:
#if (KERNEL_VERSION_MAJOR >= 4) && (KERNEL_VERSION_MINOR >= 2)
            LOG_DBG("Network event: %lld.", mgmt_event); // NOLINT
#else
            LOG_DBG("Network event: %d.", mgmt_event); // NOLINT
#endif
            break;
    }
    // NOLINTEND(hicpp-signed-bitwise)
}

#if (KERNEL_VERSION_MAJOR >= 4) && (KERNEL_VERSION_MINOR >= 2)
static void l4_mgmt_event_handler(
    struct net_mgmt_event_callback *event_cb, uint64_t mgmt_event, struct net_if *iface)
#else
static void l4_mgmt_event_handler(
    struct net_mgmt_event_callback *event_cb, uint32_t mgmt_event, struct net_if *iface)
#endif
{
    (void) event_cb;
    (void) iface;

    // NOLINTBEGIN(hicpp-signed-bitwise)
    switch (mgmt_event) {

        case NET_EVENT_L4_CONNECTED:
            LOG_DBG("Network event: NET_EVENT_L4_CONNECTED."); // NOLINT
            break;

        case NET_EVENT_L4_DISCONNECTED:
            LOG_DBG("Network event: NET_EVENT_L4_DISCONNECTED."); // NOLINT
            break;

        case NET_EVENT_DNS_SERVER_ADD:
            LOG_DBG("Network event: NET_EVENT_DNS_SERVER_ADD."); // NOLINT
            break;

        case NET_EVENT_DNS_SERVER_DEL:
            LOG_DBG("Network event: NET_EVENT_DNS_SERVER_DEL."); // NOLINT
            break;

        case NET_EVENT_HOSTNAME_CHANGED:
            LOG_DBG("Network event: NET_EVENT_HOSTNAME_CHANGED."); // NOLINT
            break;

        default:
#if (KERNEL_VERSION_MAJOR >= 4) && (KERNEL_VERSION_MINOR >= 2)
            LOG_DBG("Network event: %lld.", mgmt_event); // NOLINT
#else
            LOG_DBG("Network event: %d.", mgmt_event); // NOLINT
#endif
            break;
    }
    // NOLINTEND(hicpp-signed-bitwise)
}

/************************************************
 * Global functions definition
 ***********************************************/

int eth_connect(void)
{
    LOG_INF("Connecting through ethernet..."); // NOLINT

    // NOLINTBEGIN(hicpp-signed-bitwise, misc-redundant-expression)
    net_mgmt_init_event_callback(&eth_cb, eth_mgmt_event_handler,
        NET_EVENT_ETHERNET_CARRIER_ON | NET_EVENT_ETHERNET_CARRIER_OFF
            | NET_EVENT_ETHERNET_VLAN_TAG_ENABLED | NET_EVENT_ETHERNET_VLAN_TAG_DISABLED);
    net_mgmt_init_event_callback(&status_cb, status_mgmt_event_handler,
        NET_EVENT_IF_DOWN | NET_EVENT_IF_UP | NET_EVENT_IF_ADMIN_DOWN | NET_EVENT_IF_ADMIN_UP);
    net_mgmt_init_event_callback(&ipv6_cb, ipv6_mgmt_event_handler,
        NET_EVENT_IPV6_ADDR_ADD | NET_EVENT_IPV6_ADDR_DEL | NET_EVENT_IPV6_MADDR_ADD
            | NET_EVENT_IPV6_MADDR_DEL | NET_EVENT_IPV6_PREFIX_ADD | NET_EVENT_IPV6_PREFIX_DEL
            | NET_EVENT_IPV6_MCAST_JOIN | NET_EVENT_IPV6_MCAST_LEAVE | NET_EVENT_IPV6_ROUTER_ADD
            | NET_EVENT_IPV6_ROUTER_DEL | NET_EVENT_IPV6_ROUTE_ADD | NET_EVENT_IPV6_ROUTE_DEL
            | NET_EVENT_IPV6_DAD_SUCCEED | NET_EVENT_IPV6_DAD_FAILED | NET_EVENT_IPV6_NBR_ADD
            | NET_EVENT_IPV6_NBR_DEL | NET_EVENT_IPV6_DHCP_START | NET_EVENT_IPV6_DHCP_BOUND
            | NET_EVENT_IPV6_DHCP_STOP);
    net_mgmt_init_event_callback(&ipv4_cb, ipv4_mgmt_event_handler,
        NET_EVENT_IPV4_ADDR_ADD | NET_EVENT_IPV4_ADDR_DEL | NET_EVENT_IPV4_MADDR_ADD
            | NET_EVENT_IPV4_MADDR_DEL | NET_EVENT_IPV4_ROUTER_ADD | NET_EVENT_IPV4_ROUTER_DEL
            | NET_EVENT_IPV4_DHCP_START | NET_EVENT_IPV4_DHCP_BOUND | NET_EVENT_IPV4_DHCP_STOP
            | NET_EVENT_IPV4_MCAST_JOIN | NET_EVENT_IPV4_MCAST_LEAVE);
    net_mgmt_init_event_callback(&l4_cb, l4_mgmt_event_handler,
        NET_EVENT_L4_CONNECTED | NET_EVENT_L4_DISCONNECTED | NET_EVENT_DNS_SERVER_ADD
            | NET_EVENT_DNS_SERVER_DEL | NET_EVENT_HOSTNAME_CHANGED);
    // NOLINTEND(hicpp-signed-bitwise, misc-redundant-expression)

    net_mgmt_add_event_callback(&eth_cb);
    net_mgmt_add_event_callback(&status_cb);
    net_mgmt_add_event_callback(&ipv6_cb);
    net_mgmt_add_event_callback(&ipv4_cb);
    net_mgmt_add_event_callback(&l4_cb);

    struct net_if *iface = net_if_get_default();
    if (!iface) {
        LOG_ERR("Default interface non existant."); // NOLINT
        return -1;
    }

    LOG_INF("Waiting for Ethernet interface to be operational."); // NOLINT
    while (net_if_oper_state(iface) != NET_IF_OPER_UP) {
        k_sleep(K_MSEC(200));
    }

    const struct device *dev = net_if_get_device(iface);
    LOG_INF("Default network interface device name: %s.", dev->name); // NOLINT
    struct ethernet_context *eth_ctx = net_if_l2_data(iface);
    LOG_INF("Ethernet carrier: %s.", eth_ctx->is_net_carrier_up ? "UP" : "DOWN"); // NOLINT
    LOG_INF("Ethernet context is initialized: %s.", eth_ctx->is_init ? "YES" : "NO"); // NOLINT
    enum net_if_oper_state iface_oper_state = net_if_oper_state(iface);
    LOG_INF("Default network interface operational state: %d.", iface_oper_state); // NOLINT

#ifdef CONFIG_NET_DHCPV4
    net_dhcpv4_start(iface);

    LOG_INF("Waiting for an IPv4 address (DHCP)."); // NOLINT
    while (k_sem_count_get(&ipv4_address_obtained) == 0) {
        k_sleep(K_MSEC(200));
    }
#endif

    k_sleep(K_MSEC(500));

    LOG_INF("Ready..."); // NOLINT

    return 0;
}

void eth_poll(void)
{
    struct net_if *iface = net_if_get_default();
    if (!iface) {
        LOG_ERR("Default interface non existant."); // NOLINT
        return;
    }

    // Check if connected
    while (net_if_oper_state(iface) != NET_IF_OPER_UP) {
        LOG_WRN("Ethernet interface is non operational."); // NOLINT
        k_sleep(K_SECONDS(1));
    }

// Restart DHCP if required.
#ifdef CONFIG_NET_DHCPV4
    if (k_sem_count_get(&ipv4_address_obtained) == 0) {
        LOG_WRN("Missing IPv4 address."); // NOLINT
        net_dhcpv4_restart(iface);
        LOG_INF("Waiting for an IPv4 address (DHCP)."); // NOLINT
        while (k_sem_count_get(&ipv4_address_obtained) == 0) {
            k_sleep(K_MSEC(200));
        }
        LOG_INF("Ready..."); // NOLINT
    }
#endif

    k_sleep(K_MSEC(500));
}
```
